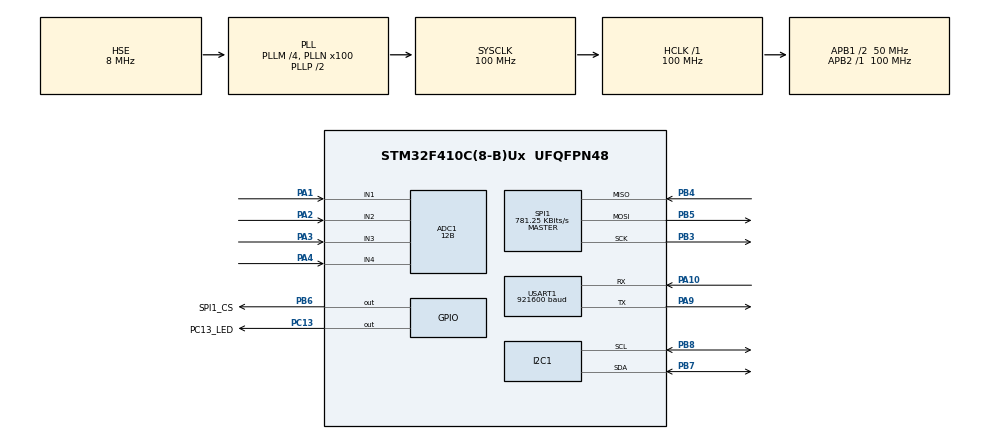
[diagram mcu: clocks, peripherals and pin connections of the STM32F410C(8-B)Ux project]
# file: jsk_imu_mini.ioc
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ADC1.Channel-0\#ChannelRegularConversion=ADC_CHANNEL_1
ADC1.Channel-1\#ChannelRegularConversion=ADC_CHANNEL_2
ADC1.Channel-2\#ChannelRegularConversion=ADC_CHANNEL_3
ADC1.Channel-3\#ChannelRegularConversion=ADC_CHANNEL_4
ADC1.ClockPrescaler=ADC_CLOCK_SYNC_PCLK_DIV4
ADC1.ContinuousConvMode=DISABLE
ADC1.DMAContinuousRequests=DISABLE
ADC1.DataAlign=ADC_DATAALIGN_RIGHT
ADC1.DiscontinuousConvMode=DISABLE
ADC1.EOCSelection=ADC_EOC_SINGLE_CONV
ADC1.EnableAnalogWatchDog=false
ADC1.ExternalTrigConv=ADC_SOFTWARE_START
ADC1.ExternalTrigConvEdge=ADC_EXTERNALTRIGCONVEDGE_NONE
ADC1.InjNumberOfConversion=0
ADC1.NbrOfConversion=4
ADC1.NbrOfConversionFlag=1
ADC1.Rank-0\#ChannelRegularConversion=1
ADC1.Rank-1\#ChannelRegularConversion=2
ADC1.Rank-2\#ChannelRegularConversion=3
ADC1.Rank-3\#ChannelRegularConversion=4
ADC1.Resolution=ADC_RESOLUTION_12B
ADC1.SamplingTime-0\#ChannelRegularConversion=ADC_SAMPLETIME_28CYCLES
ADC1.SamplingTime-1\#ChannelRegularConversion=ADC_SAMPLETIME_28CYCLES
ADC1.SamplingTime-2\#ChannelRegularConversion=ADC_SAMPLETIME_28CYCLES
ADC1.SamplingTime-3\#ChannelRegularConversion=ADC_SAMPLETIME_28CYCLES
ADC1.ScanConvMode=ENABLE
ADC1.master=1
Dma.Request0=USART1_RX
Dma.Request1=USART1_TX
Dma.USART1_RX.0.Direction=DMA_PERIPH_TO_MEMORY
Dma.USART1_RX.0.FIFOMode=DMA_FIFOMODE_ENABLE
Dma.USART1_RX.0.FIFOThreshold=DMA_FIFO_THRESHOLD_HALFFULL
Dma.USART1_RX.0.Instance=DMA2_Stream2
Dma.USART1_RX.0.MemBurst=DMA_MBURST_INC8
Dma.USART1_RX.0.MemDataAlignment=DMA_MDATAALIGN_BYTE
Dma.USART1_RX.0.MemInc=DMA_MINC_ENABLE
Dma.USART1_RX.0.Mode=DMA_CIRCULAR
Dma.USART1_RX.0.PeriphBurst=DMA_PBURST_SINGLE
Dma.USART1_RX.0.PeriphDataAlignment=DMA_PDATAALIGN_BYTE
Dma.USART1_RX.0.PeriphInc=DMA_PINC_DISABLE
Dma.USART1_RX.0.Priority=DMA_PRIORITY_VERY_HIGH
Dma.USART1_TX.1.Direction=DMA_MEMORY_TO_PERIPH
Dma.USART1_TX.1.FIFOMode=DMA_FIFOMODE_DISABLE
Dma.USART1_TX.1.Instance=DMA2_Stream7
Dma.USART1_TX.1.MemDataAlignment=DMA_MDATAALIGN_BYTE
Dma.USART1_TX.1.MemInc=DMA_MINC_ENABLE
Dma.USART1_TX.1.Mode=DMA_CIRCULAR
Dma.USART1_TX.1.PeriphDataAlignment=DMA_PDATAALIGN_BYTE
Dma.USART1_TX.1.PeriphInc=DMA_PINC_DISABLE
Dma.USART1_TX.1.Priority=DMA_PRIORITY_VERY_HIGH
Mcu.Family=STM32F4
Mcu.Name=STM32F410C(8-B)Ux
Mcu.Package=UFQFPN48
NVIC.DMA2_Stream2_IRQn=true\:2\:1\:true\:false\:true\:false\:true
NVIC.DMA2_Stream7_IRQn=true\:2\:1\:true\:false\:true\:false\:true
NVIC.PriorityGroup=NVIC_PRIORITYGROUP_2
NVIC.SPI1_IRQn=true\:0\:0\:false\:false\:true\:true\:true
NVIC.USART1_IRQn=true\:0\:0\:false\:false\:true\:true\:true
PA1.Signal=ADCx_IN1
PA10.Mode=Asynchronous
PA10.Signal=USART1_RX
PA2.Signal=ADCx_IN2
PA3.Signal=ADCx_IN3
PA4.Signal=ADCx_IN4
PA9.Mode=Asynchronous
PA9.Signal=USART1_TX
PB3.Mode=Full_Duplex_Master
PB3.Signal=SPI1_SCK
PB4.Mode=Full_Duplex_Master
PB4.Signal=SPI1_MISO
PB5.Mode=Full_Duplex_Master
PB5.Signal=SPI1_MOSI
PB6.GPIO_Label=SPI1_CS
PB6.GPIO_PuPd=GPIO_PULLUP
PB6.GPIO_Speed=GPIO_SPEED_FREQ_HIGH
PB6.Signal=GPIO_Output
PB7.Mode=I2C
PB7.Signal=I2C1_SDA
PB8.Mode=I2C
PB8.Signal=I2C1_SCL
PC13-ANTI_TAMP.GPIO_Label=PC13_LED
PC13-ANTI_TAMP.GPIO_ModeDefaultOutputPP=GPIO_MODE_OUTPUT_OD
PC13-ANTI_TAMP.GPIO_PuPd=GPIO_PULLUP
PC13-ANTI_TAMP.Signal=GPIO_Output
PH0\ -\ OSC_IN.Mode=HSE-External-Oscillator
PH0\ -\ OSC_IN.Signal=RCC_OSC_IN
PH1\ -\ OSC_OUT.Mode=HSE-External-Oscillator
PH1\ -\ OSC_OUT.Signal=RCC_OSC_OUT
ProjectManager.HeapSize=0x200
ProjectManager.StackSize=0x400
ProjectManager.TargetToolchain=Makefile
RCC.48MHZClocksFreq_Value=50000000
RCC.AHBFreq_Value=100000000
RCC.APB1CLKDivider=RCC_HCLK_DIV2
RCC.APB1Freq_Value=50000000
RCC.APB1TimFreq_Value=100000000
RCC.APB2Freq_Value=100000000
RCC.APB2TimFreq_Value=100000000
RCC.CortexFreq_Value=100000000
RCC.HCLKFreq_Value=100000000
RCC.HSE_VALUE=8000000
RCC.HSI_VALUE=16000000
RCC.LSE_VALUE=32768
RCC.PLLM=4
RCC.PLLN=100
RCC.PLLSourceVirtual=RCC_PLLSOURCE_HSE
RCC.SYSCLKFreq_VALUE=100000000
RCC.SYSCLKSource=RCC_SYSCLKSOURCE_PLLCLK
RCC.VCOOutputFreq_Value=200000000
SH.ADCx_IN1.0=ADC1_IN1,IN1
SH.ADCx_IN2.0=ADC1_IN2,IN2
SH.ADCx_IN3.0=ADC1_IN3,IN3
SH.ADCx_IN4.0=ADC1_IN4,IN4
SPI1.BaudRatePrescaler=SPI_BAUDRATEPRESCALER_128
SPI1.CalculateBaudRate=781.25 KBits/s
SPI1.Direction=SPI_DIRECTION_2LINES
SPI1.Mode=SPI_MODE_MASTER
SPI1.VirtualType=VM_MASTER
USART1.BaudRate=921600
USART1.VirtualMode=VM_ASYNC
VP_IWDG_VS_IWDG.Mode=IWDG_Activate
board=jsk_imu_mini

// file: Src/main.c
/**
  ******************************************************************************
  * File Name          : main.c
  * Description        : Main program body
  ******************************************************************************
  ** This notice applies to any and all portions of this file
  * that are not between comment pairs USER CODE BEGIN and
  * USER CODE END. Other portions of this file, whether
  * inserted by the user or by software development tools
  * are owned by their respective copyright owners.
  *
  * COPYRIGHT(c) 2017 STMicroelectronics
  *
  * Redistribution and use in source and binary forms, with or without modification,
  * are permitted provided that the following conditions are met:
  *   1. Redistributions of source code must retain the above copyright notice,
  *      this list of conditions and the following disclaimer.
  *   2. Redistributions in binary form must reproduce the above copyright notice,
  *      this list of conditions and the following disclaimer in the documentation
  *      and/or other materials provided with the distribution.
  *   3. Neither the name of STMicroelectronics nor the names of its contributors
  *      may be used to endorse or promote products derived from this software
  *      without specific prior written permission.
  *
  * THIS SOFTWARE IS PROVIDED BY THE COPYRIGHT HOLDERS AND CONTRIBUTORS "AS IS"
  * AND ANY EXPRESS OR IMPLIED WARRANTIES, INCLUDING, BUT NOT LIMITED TO, THE
  * IMPLIED WARRANTIES OF MERCHANTABILITY AND FITNESS FOR A PARTICULAR PURPOSE ARE
  * DISCLAIMED. IN NO EVENT SHALL THE COPYRIGHT HOLDER OR CONTRIBUTORS BE LIABLE
  * FOR ANY DIRECT, INDIRECT, INCIDENTAL, SPECIAL, EXEMPLARY, OR CONSEQUENTIAL
  * DAMAGES (INCLUDING, BUT NOT LIMITED TO, PROCUREMENT OF SUBSTITUTE GOODS OR
  * SERVICES; LOSS OF USE, DATA, OR PROFITS; OR BUSINESS INTERRUPTION) HOWEVER
  * CAUSED AND ON ANY THEORY OF LIABILITY, WHETHER IN CONTRACT, STRICT LIABILITY,
  * OR TORT (INCLUDING NEGLIGENCE OR OTHERWISE) ARISING IN ANY WAY OUT OF THE USE
  * OF THIS SOFTWARE, EVEN IF ADVISED OF THE POSSIBILITY OF SUCH DAMAGE.
  *
  ******************************************************************************
  */

#include "main.h"
#include "stm32f4xx_hal.h"
#include "adc.h"
#include "dma.h"
#include "i2c.h"
#include "iwdg.h"
#include "spi.h"
#include "usart.h"
#include "gpio.h"

/* USER CODE BEGIN PV */
/* Private variables ---------------------------------------------------------*/

/* USER CODE END PV */

void SystemClock_Config(void);

/* USER CODE BEGIN PFP */
/* Private function prototypes -----------------------------------------------*/

/* USER CODE END PFP */

int main(void)
{

  /* MCU Configuration----------------------------------------------------------*/

  /* Reset of all peripherals, Initializes the Flash interface and the Systick. */
  HAL_Init();

  /* Configure the system clock */
  SystemClock_Config();

  /* Initialize all configured peripherals */
  MX_GPIO_Init();
  MX_DMA_Init();
  MX_USART1_UART_Init();
  MX_SPI1_Init();
  MX_ADC1_Init();
  MX_I2C1_Init();
  MX_IWDG_Init();

  /* Infinite loop */
  while (1)
  {

  /* USER CODE BEGIN 3 */
	  HAL_GPIO_TogglePin(GPIO_PIN_13,GPIOC);
	  HAL_Delay(200);
  }
  /* USER CODE END 3 */

}

/** System Clock Configuration
*/
void SystemClock_Config(void)
{

  RCC_OscInitTypeDef RCC_OscInitStruct;
  RCC_ClkInitTypeDef RCC_ClkInitStruct;

    /**Configure the main internal regulator output voltage
    */
  __HAL_RCC_PWR_CLK_ENABLE();

  __HAL_PWR_VOLTAGESCALING_CONFIG(PWR_REGULATOR_VOLTAGE_SCALE1);

    /**Initializes the CPU, AHB and APB busses clocks
    */
  RCC_OscInitStruct.OscillatorType = RCC_OSCILLATORTYPE_LSI|RCC_OSCILLATORTYPE_HSE;
  RCC_OscInitStruct.HSEState = RCC_HSE_ON;
  RCC_OscInitStruct.LSIState = RCC_LSI_ON;
  RCC_OscInitStruct.PLL.PLLState = RCC_PLL_ON;
  RCC_OscInitStruct.PLL.PLLSource = RCC_PLLSOURCE_HSE;
  RCC_OscInitStruct.PLL.PLLM = 4;
  RCC_OscInitStruct.PLL.PLLN = 100;
  RCC_OscInitStruct.PLL.PLLP = RCC_PLLP_DIV2;
  RCC_OscInitStruct.PLL.PLLQ = 4;
  RCC_OscInitStruct.PLL.PLLR = 2;
  if (HAL_RCC_OscConfig(&RCC_OscInitStruct) != HAL_OK)
  {
    _Error_Handler(__FILE__, __LINE__);
  }

    /**Initializes the CPU, AHB and APB busses clocks
    */
  RCC_ClkInitStruct.ClockType = RCC_CLOCKTYPE_HCLK|RCC_CLOCKTYPE_SYSCLK
                              |RCC_CLOCKTYPE_PCLK1|RCC_CLOCKTYPE_PCLK2;
  RCC_ClkInitStruct.SYSCLKSource = RCC_SYSCLKSOURCE_PLLCLK;
  RCC_ClkInitStruct.AHBCLKDivider = RCC_SYSCLK_DIV1;
  RCC_ClkInitStruct.APB1CLKDivider = RCC_HCLK_DIV2;
  RCC_ClkInitStruct.APB2CLKDivider = RCC_HCLK_DIV1;

  if (HAL_RCC_ClockConfig(&RCC_ClkInitStruct, FLASH_LATENCY_3) != HAL_OK)
  {
    _Error_Handler(__FILE__, __LINE__);
  }

    /**Configure the Systick interrupt time
    */
  HAL_SYSTICK_Config(HAL_RCC_GetHCLKFreq()/1000);

    /**Configure the Systick
    */
  HAL_SYSTICK_CLKSourceConfig(SYSTICK_CLKSOURCE_HCLK);

  /* SysTick_IRQn interrupt configuration */
  HAL_NVIC_SetPriority(SysTick_IRQn, 0, 1);
}

void _Error_Handler(char * file, int line)
{
  while(1)
  {
  }
}

/************************ (C) COPYRIGHT STMicroelectronics *****END OF FILE****/
